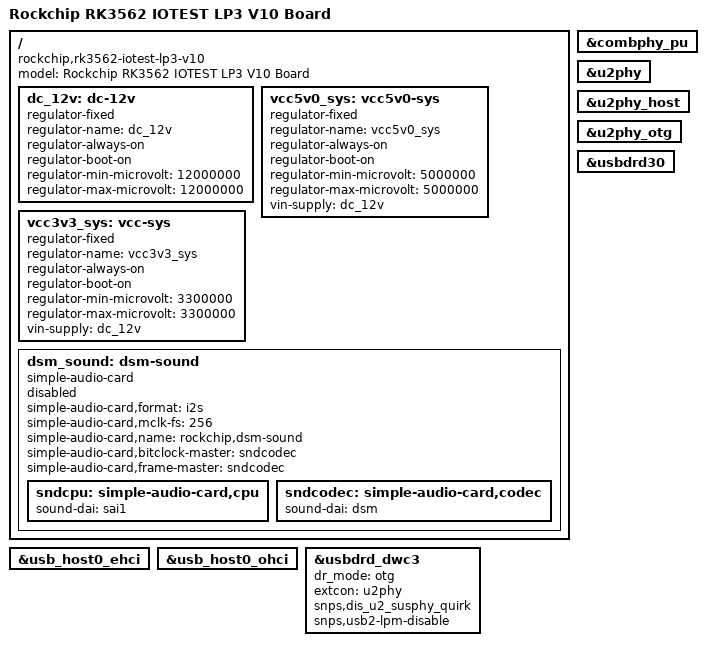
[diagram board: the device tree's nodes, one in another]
// SPDX-License-Identifier: (GPL-2.0+ OR MIT)
/*
 * Copyright (c) 2023 Rockchip Electronics Co., Ltd.
 *
 */

/dts-v1/;

#include "rk3562.dtsi"
#include "rk3562-linux.dtsi"

/ {
	model = "Rockchip RK3562 IOTEST LP3 V10 Board";
	compatible = "rockchip,rk3562-iotest-lp3-v10", "rockchip,rk3562";

	dc_12v: dc-12v {
		compatible = "regulator-fixed";
		regulator-name = "dc_12v";
		regulator-always-on;
		regulator-boot-on;
		regulator-min-microvolt = <12000000>;
		regulator-max-microvolt = <12000000>;
	};

	vcc5v0_sys: vcc5v0-sys {
		compatible = "regulator-fixed";
		regulator-name = "vcc5v0_sys";
		regulator-always-on;
		regulator-boot-on;
		regulator-min-microvolt = <5000000>;
		regulator-max-microvolt = <5000000>;
		vin-supply = <&dc_12v>;
	};

	vcc3v3_sys: vcc-sys {
		compatible = "regulator-fixed";
		regulator-name = "vcc3v3_sys";
		regulator-always-on;
		regulator-boot-on;
		regulator-min-microvolt = <3300000>;
		regulator-max-microvolt = <3300000>;
		vin-supply = <&dc_12v>;
	};

	dsm_sound: dsm-sound {
		status = "disabled";
		compatible = "simple-audio-card";
		simple-audio-card,format = "i2s";
		simple-audio-card,mclk-fs = <256>;
		simple-audio-card,name = "rockchip,dsm-sound";
		simple-audio-card,bitclock-master = <&sndcodec>;
		simple-audio-card,frame-master = <&sndcodec>;
		sndcpu: simple-audio-card,cpu {
			sound-dai = <&sai1>;
		};
		sndcodec: simple-audio-card,codec {
			sound-dai = <&dsm>;
		};
	};
};

#include "rk3562-rk809.dtsi"

&combphy_pu {
	status = "okay";
};

&u2phy {
	status = "okay";
};

&u2phy_host {
	status = "okay";
};

&u2phy_otg {
	status = "okay";
};

&usb_host0_ehci {
	status = "okay";
};

&usb_host0_ohci {
	status = "okay";
};

&usbdrd30 {
	status = "okay";
};

&usbdrd_dwc3 {
	status = "okay";
	dr_mode = "otg";
	extcon = <&u2phy>;
	snps,dis_u2_susphy_quirk;
	snps,usb2-lpm-disable;
};
